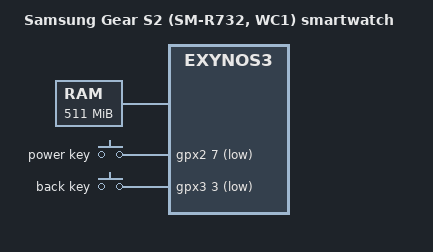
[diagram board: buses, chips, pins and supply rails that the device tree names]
// SPDX-License-Identifier: GPL-2.0
/*
 * Device tree from Gear S2 Classic (WC1).
 *
 * TODO: Adjust parts based on reading downstream Samsung kernel sources
 *
 * Some parts based on:
 *
 * Samsung's Exynos3250 based Rinato board device tree source
 *
 * Copyright (c) 2014 Samsung Electronics Co., Ltd.
 *		http://www.samsung.com
 *
 * Device tree source file for Samsung's Rinato board which is based on
 * Samsung Exynos3250 SoC.
 */

/dts-v1/;
#include "exynos3250.dtsi"
#include "exynos4412-ppmu-common.dtsi"
#include <dt-bindings/input/input.h>
#include <dt-bindings/gpio/gpio.h>
#include <dt-bindings/clock/samsung,s2mps11.h>

/ {
	model = "Samsung Gear S2 (SM-R732, WC1) smartwatch";
	// Might need tweaks similar to https://patchwork.kernel.org/project/linux-arm-kernel/patch/1415360662-30390-1-git-send-email-k.kozlowski@samsung.com/
	compatible = "samsung,wc1", "samsung,exynos3250", "samsung,exynos3";

	/* X-check w/ downstream kernel - likely correct */
	memory@40000000 {
		device_type = "memory";
		reg = <0x40000000 0x1ff00000>;
	};

	/* X-check w/ downstream kernel - likely correct */
	/* This is incomplete. Inputs based on board-orbis-input.c in downstream kernel. */
	gpio-keys {
		compatible = "gpio-keys";

		power-key {
			gpios = <&gpx2 7 GPIO_ACTIVE_LOW>;
			linux,code = <KEY_POWER>;
			label = "power key";
			debounce-interval = <20>;
			wakeup-source;
		};

		back-key {
			gpios = <&gpx3 3 GPIO_ACTIVE_LOW>;
			label = "back key";
			debounce-interval = <20>;
			/* TODO: Fill out further */
		};
		/* TODO: All the rest (crown, hall sensor...) */
	};
};
